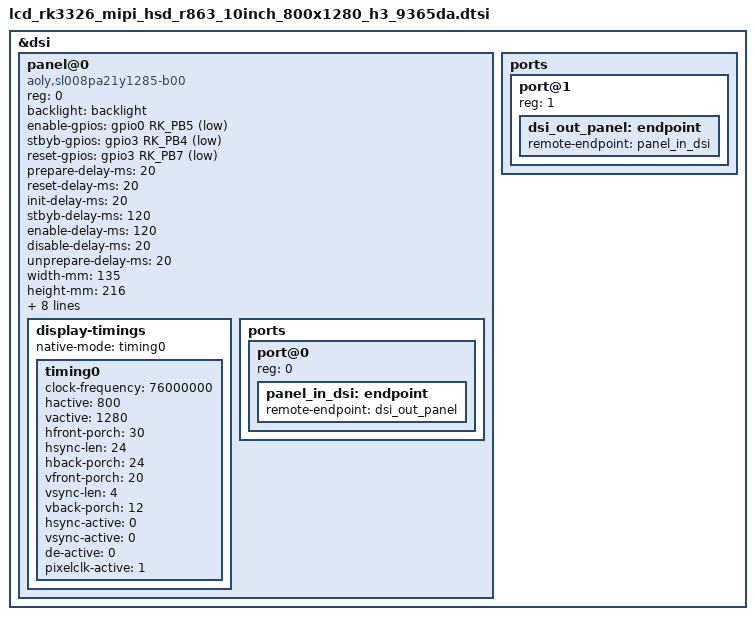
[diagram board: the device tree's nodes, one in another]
/*
* incar mipi lcd
*/
&dsi {
	status = "okay";

	panel@0 {
		compatible = "aoly,sl008pa21y1285-b00", "simple-panel-dsi";
		reg = <0>;
		backlight = <&backlight>;
		enable-gpios = <&gpio0 RK_PB5 GPIO_ACTIVE_LOW>;
		stbyb-gpios = <&gpio3 RK_PB4 GPIO_ACTIVE_LOW>;
		
		reset-gpios = <&gpio3 RK_PB7 GPIO_ACTIVE_LOW>;
		prepare-delay-ms = <20>;
		reset-delay-ms = <20>;
		init-delay-ms = <20>;
		stbyb-delay-ms = <120>;
		enable-delay-ms = <120>;
		disable-delay-ms = <20>;
		unprepare-delay-ms = <20>;

		width-mm = <135>;
		height-mm = <216>;

		dsi,flags = <(MIPI_DSI_MODE_VIDEO | MIPI_DSI_MODE_VIDEO_BURST |
			      MIPI_DSI_MODE_LPM | MIPI_DSI_MODE_EOT_PACKET)>;
		dsi,format = <MIPI_DSI_FMT_RGB888>;
		dsi,lanes = <4>;

		panel-init-sequence = [
		
		15 00 02  E0 00 

		15 00 02  E1 93 
		15 00 02  E2 65 
		15 00 02  E3 F8 
		15 00 02  80 03 

		15 00 02  E0 01 

		15 00 02  00 00 
		15 00 02  01 46 
		15 00 02  03 00 
		15 00 02  04 3B 

		15 00 02  0C 74 

		15 00 02  17 00 
		15 00 02  18 EF 
		15 00 02  19 00 
		15 00 02  1A 00 
		15 00 02  1B EF 
		15 00 02  1C 00 

		15 00 02  24 FE 
		15 00 02  25 20 
		15 00 02  35 23 

		15 00 02  37 59 

		15 00 02  38 05 
		15 00 02  39 08 
		15 00 02  3A 12 
		15 00 02  3C 78 
		15 00 02  3D FF 
		15 00 02  3E FF 
		15 00 02  3F FF 


		15 00 02  40 06 
		15 00 02  41 A0 
		15 00 02  43 14 
		15 00 02  44 0F 
		15 00 02  45 30 


		15 00 02  55 02 
		15 00 02  57 A9 
		15 00 02  59 0E 
		15 00 02  5A 38 
		15 00 02  5B 10 

		15 00 02  5D 7A 
		15 00 02  5E 5B 
		15 00 02  5F 4C 
		15 00 02  60 42 
		15 00 02  61 41 
		15 00 02  62 36 
		15 00 02  63 3F 
		15 00 02  64 2C 
		15 00 02  65 48 
		15 00 02  66 47 
		15 00 02  67 45 
		15 00 02  68 5E 
		15 00 02  69 49 
		15 00 02  6A 4E 
		15 00 02  6B 41 
		15 00 02  6C 3F 
		15 00 02  6D 35 
		15 00 02  6E 27 
		15 00 02  6F 10 
		15 00 02  70 7A 
		15 00 02  71 5B 
		15 00 02  72 4C 
		15 00 02  73 42 
		15 00 02  74 41 
		15 00 02  75 36 
		15 00 02  76 3F 
		15 00 02  77 2C 
		15 00 02  78 48 
		15 00 02  79 47 
		15 00 02  7A 45 
		15 00 02  7B 5E 
		15 00 02  7C 49 
		15 00 02  7D 4E 
		15 00 02  7E 41 
		15 00 02  7F 3F 
		15 00 02  80 35 
		15 00 02  81 27 
		15 00 02  82 10 

		15 00 02  E0 02 

		15 00 02  00 5E 
		15 00 02  01 5F 
		15 00 02  02 57 
		15 00 02  03 77 
		15 00 02  04 48 
		15 00 02  05 4A 
		15 00 02  06 44 
		15 00 02  07 46 
		15 00 02  08 40 
		15 00 02  09 5F 
		15 00 02  0A 5F 
		15 00 02  0B 5F 
		15 00 02  0C 5F 
		15 00 02  0D 5F 
		15 00 02  0E 5F 
		15 00 02  0F 42 
		15 00 02  10 5F 
		15 00 02  11 5F 
		15 00 02  12 5F 
		15 00 02  13 5F 
		15 00 02  14 5F 
		15 00 02  15 5F 

		15 00 02  16 5E 
		15 00 02  17 5F 
		15 00 02  18 57 
		15 00 02  19 77 
		15 00 02  1A 49 
		15 00 02  1B 4B 
		15 00 02  1C 45 
		15 00 02  1D 47 
		15 00 02  1E 41 
		15 00 02  1F 5F 
		15 00 02  20 5F 
		15 00 02  21 5F 
		15 00 02  22 5F 
		15 00 02  23 5F 
		15 00 02  24 5F 
		15 00 02  25 43 
		15 00 02  26 5F 
		15 00 02  27 5F 
		15 00 02  28 5F 
		15 00 02  29 5F 
		15 00 02  2A 5F 
		15 00 02  2B 5F 

		15 00 02  2C 1F 
		15 00 02  2D 1E 
		15 00 02  2E 17 
		15 00 02  2F 17 
		15 00 02  30 07 
		15 00 02  31 05 
		15 00 02  32 0B 
		15 00 02  33 09 
		15 00 02  34 03 
		15 00 02  35 1F 
		15 00 02  36 1F 
		15 00 02  37 1F 
		15 00 02  38 1F 
		15 00 02  39 1F 
		15 00 02  3A 1F 
		15 00 02  3B 01 
		15 00 02  3C 1F 
		15 00 02  3D 1F 
		15 00 02  3E 1F 
		15 00 02  3F 1F 
		15 00 02  40 1F 
		15 00 02  41 1F 

		15 00 02  42 1F 
		15 00 02  43 1E 
		15 00 02  44 17 
		15 00 02  45 17 
		15 00 02  46 06 
		15 00 02  47 04 
		15 00 02  48 0A 
		15 00 02  49 08 
		15 00 02  4A 02 
		15 00 02  4B 1F 
		15 00 02  4C 1F 
		15 00 02  4D 1F 
		15 00 02  4E 1F 
		15 00 02  4F 1F 
		15 00 02  50 1F 
		15 00 02  51 00 
		15 00 02  52 1F 
		15 00 02  53 1F 
		15 00 02  54 1F 
		15 00 02  55 1F 
		15 00 02  56 1F 
		15 00 02  57 1F 

		15 00 02  58 40 
		15 00 02  59 00 
		15 00 02  5A 00 
		15 00 02  5B 30 
		15 00 02  5C 05 
		15 00 02  5D 30 
		15 00 02  5E 01 
		15 00 02  5F 02 
		15 00 02  60 30 
		15 00 02  61 03 
		15 00 02  62 04 
		15 00 02  63 03 
		15 00 02  64 6A 
		15 00 02  65 75 
		15 00 02  66 0D 
		15 00 02  67 73 
		15 00 02  68 09 
		15 00 02  69 06 
		15 00 02  6A 6A 
		15 00 02  6B 08 
		15 00 02  6C 00 
		15 00 02  6D 0C 
		15 00 02  6E 04 
		15 00 02  6F 88 
		15 00 02  70 00 
		15 00 02  71 00 
		15 00 02  72 06 
		15 00 02  73 7B 
		15 00 02  74 00 
		15 00 02  75 BC 
		15 00 02  76 00 
		15 00 02  77 0D 
		15 00 02  78 24 
		15 00 02  79 00 
		15 00 02  7A 00 
		15 00 02  7B 00 
		15 00 02  7C 00 
		15 00 02  7D 03 
		15 00 02  7E 7B 

		15 00 02  E0 04 
		15 00 02  00 0E 
		15 00 02  02 B3 
		15 00 02  09 60 
		15 00 02  0E 48 

		15 00 02  E0 00 
		05 78 01 11 
		05 14 01 29 
		
		
		];

		panel-exit-sequence = [
			05 14 01 28
			05 78 01 10
		];


		display-timings {
			native-mode = <&timing0>;

			timing0: timing0 {
				clock-frequency = <76000000>;
				hactive = <800>;
				vactive = <1280>;
				hfront-porch = <30>;
				hsync-len = <24>;
				hback-porch = <24>;
				vfront-porch = <20>;
				vsync-len = <4>;
				vback-porch = <12>;
				
				
				
				hsync-active = <0>;
				vsync-active = <0>;
				de-active = <0>;
				pixelclk-active = <1>;
			};
		};
		ports {
			#address-cells = <1>;
			#size-cells = <0>;

			port@0 {
				reg = <0>;
				panel_in_dsi: endpoint {
					remote-endpoint = <&dsi_out_panel>;
				};
			};
		};
	};

	ports {
		#address-cells = <1>;
		#size-cells = <0>;

		port@1 {
			reg = <1>;
			dsi_out_panel: endpoint {
				remote-endpoint = <&panel_in_dsi>;
			};
		};
	};
};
